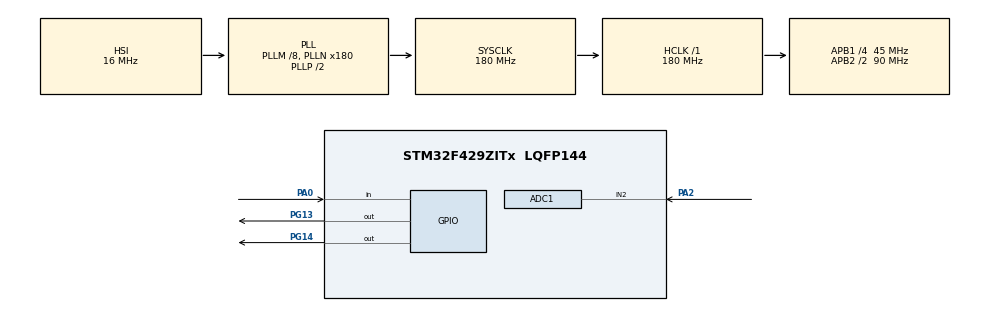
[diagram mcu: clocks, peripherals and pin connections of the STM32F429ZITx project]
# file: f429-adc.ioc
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ADC1.Channel-0\#ChannelRegularConversion=ADC_CHANNEL_2
ADC1.ContinuousConvMode=ENABLE
ADC1.EOCSelection=ADC_EOC_SEQ_CONV
ADC1.NbrOfConversion=1
ADC1.NbrOfConversionFlag=1
ADC1.Rank-0\#ChannelRegularConversion=1
ADC1.Resolution=ADC_RESOLUTION_6B
ADC1.SamplingTime-0\#ChannelRegularConversion=ADC_SAMPLETIME_56CYCLES
ADC1.master=1
Mcu.Family=STM32F4
Mcu.Name=STM32F429ZITx
Mcu.Package=LQFP144
NVIC.PriorityGroup=NVIC_PRIORITYGROUP_4
PA0/WKUP.Signal=GPIO_Input
PA2.Signal=ADCx_IN2
PG13.GPIO_Speed=GPIO_SPEED_FREQ_VERY_HIGH
PG13.Signal=GPIO_Output
PG14.GPIO_Speed=GPIO_SPEED_FREQ_VERY_HIGH
PG14.Signal=GPIO_Output
PH0/OSC_IN.Mode=HSE-External-Oscillator
PH0/OSC_IN.Signal=RCC_OSC_IN
PH1/OSC_OUT.Mode=HSE-External-Oscillator
PH1/OSC_OUT.Signal=RCC_OSC_OUT
ProjectManager.HeapSize=0x200
ProjectManager.StackSize=0x400
ProjectManager.TargetToolchain=MDK-ARM V5.27
RCC.48MHZClocksFreq_Value=90000000
RCC.AHBFreq_Value=180000000
RCC.APB1CLKDivider=RCC_HCLK_DIV4
RCC.APB1Freq_Value=45000000
RCC.APB1TimFreq_Value=90000000
RCC.APB2CLKDivider=RCC_HCLK_DIV2
RCC.APB2Freq_Value=90000000
RCC.APB2TimFreq_Value=180000000
RCC.CortexFreq_Value=180000000
RCC.HCLKFreq_Value=180000000
RCC.HSE_VALUE=8000000
RCC.HSI_VALUE=16000000
RCC.LSE_VALUE=32768
RCC.PLLM=8
RCC.PLLN=180
RCC.SYSCLKFreq_VALUE=180000000
RCC.SYSCLKSource=RCC_SYSCLKSOURCE_PLLCLK
RCC.VCOOutputFreq_Value=360000000
SH.ADCx_IN2.0=ADC1_IN2,IN2
board=custom

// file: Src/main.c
/* USER CODE BEGIN Header */
/**
  ******************************************************************************
  * @file           : main.c
  * @brief          : Main program body
  ******************************************************************************
  * @attention
  *
  * <h2><center>&copy; Copyright (c) 2020 STMicroelectronics.
  * All rights reserved.</center></h2>
  *
  * This software component is licensed by ST under BSD 3-Clause license,
  * the "License"; You may not use this file except in compliance with the
  * License. You may obtain a copy of the License at:
  *                        opensource.org/licenses/BSD-3-Clause
  *
  ******************************************************************************
  */
/* USER CODE END Header */

#include "main.h"

/* USER CODE BEGIN PTD */

int ADC_Value = 0;

/* USER CODE END PTD */

ADC_HandleTypeDef hadc1;

void SystemClock_Config(void);
static void MX_GPIO_Init(void);
static void MX_ADC1_Init(void);

int main(void)
{

  /* MCU Configuration--------------------------------------------------------*/

  /* Reset of all peripherals, Initializes the Flash interface and the Systick. */
  HAL_Init();

  /* Configure the system clock */
  SystemClock_Config();

  /* Initialize all configured peripherals */
  MX_GPIO_Init();
  MX_ADC1_Init();
  /* USER CODE BEGIN 2 */

	HAL_ADC_Start(&hadc1);

	HAL_GPIO_WritePin(GPIOG, GPIO_PIN_14, GPIO_PIN_SET);

  /* USER CODE END 2 */

  /* Infinite loop */
  while (1)
  {

    /* USER CODE BEGIN 3 */

		if(HAL_ADC_PollForConversion(&hadc1, 100) == HAL_OK)
		{

			ADC_Value = HAL_ADC_GetValue(&hadc1);

		}

		if(HAL_GPIO_ReadPin(GPIOA, GPIO_PIN_0))
		{
			while(HAL_GPIO_ReadPin(GPIOA, GPIO_PIN_0));
			HAL_Delay(100);
			HAL_GPIO_TogglePin(GPIOG, GPIO_PIN_13);
			HAL_GPIO_TogglePin(GPIOG, GPIO_PIN_14);

		}

  }
  /* USER CODE END 3 */
}

void SystemClock_Config(void)
{
  RCC_OscInitTypeDef RCC_OscInitStruct = {0};
  RCC_ClkInitTypeDef RCC_ClkInitStruct = {0};

  /** Configure the main internal regulator output voltage
  */
  __HAL_RCC_PWR_CLK_ENABLE();
  __HAL_PWR_VOLTAGESCALING_CONFIG(PWR_REGULATOR_VOLTAGE_SCALE1);
  /** Initializes the CPU, AHB and APB busses clocks
  */
  RCC_OscInitStruct.OscillatorType = RCC_OSCILLATORTYPE_HSI;
  RCC_OscInitStruct.HSIState = RCC_HSI_ON;
  RCC_OscInitStruct.HSICalibrationValue = RCC_HSICALIBRATION_DEFAULT;
  RCC_OscInitStruct.PLL.PLLState = RCC_PLL_ON;
  RCC_OscInitStruct.PLL.PLLSource = RCC_PLLSOURCE_HSI;
  RCC_OscInitStruct.PLL.PLLM = 8;
  RCC_OscInitStruct.PLL.PLLN = 180;
  RCC_OscInitStruct.PLL.PLLP = RCC_PLLP_DIV2;
  RCC_OscInitStruct.PLL.PLLQ = 4;
  if (HAL_RCC_OscConfig(&RCC_OscInitStruct) != HAL_OK)
  {
    Error_Handler();
  }
  /** Activate the Over-Drive mode
  */
  if (HAL_PWREx_EnableOverDrive() != HAL_OK)
  {
    Error_Handler();
  }
  /** Initializes the CPU, AHB and APB busses clocks
  */
  RCC_ClkInitStruct.ClockType = RCC_CLOCKTYPE_HCLK|RCC_CLOCKTYPE_SYSCLK
                              |RCC_CLOCKTYPE_PCLK1|RCC_CLOCKTYPE_PCLK2;
  RCC_ClkInitStruct.SYSCLKSource = RCC_SYSCLKSOURCE_PLLCLK;
  RCC_ClkInitStruct.AHBCLKDivider = RCC_SYSCLK_DIV1;
  RCC_ClkInitStruct.APB1CLKDivider = RCC_HCLK_DIV4;
  RCC_ClkInitStruct.APB2CLKDivider = RCC_HCLK_DIV2;

  if (HAL_RCC_ClockConfig(&RCC_ClkInitStruct, FLASH_LATENCY_5) != HAL_OK)
  {
    Error_Handler();
  }
}

static void MX_ADC1_Init(void)
{

  ADC_ChannelConfTypeDef sConfig = {0};

  /** Configure the global features of the ADC (Clock, Resolution, Data Alignment and number of conversion)
  */
  hadc1.Instance = ADC1;
  hadc1.Init.ClockPrescaler = ADC_CLOCK_SYNC_PCLK_DIV4;
  hadc1.Init.Resolution = ADC_RESOLUTION_8B;
  hadc1.Init.ScanConvMode = DISABLE;
  hadc1.Init.ContinuousConvMode = ENABLE;
  hadc1.Init.DiscontinuousConvMode = DISABLE;
  hadc1.Init.ExternalTrigConvEdge = ADC_EXTERNALTRIGCONVEDGE_NONE;
  hadc1.Init.ExternalTrigConv = ADC_SOFTWARE_START;
  hadc1.Init.DataAlign = ADC_DATAALIGN_RIGHT;
  hadc1.Init.NbrOfConversion = 1;
  hadc1.Init.DMAContinuousRequests = DISABLE;
  hadc1.Init.EOCSelection = ADC_EOC_SEQ_CONV;
  if (HAL_ADC_Init(&hadc1) != HAL_OK)
  {
    Error_Handler();
  }
  /** Configure for the selected ADC regular channel its corresponding rank in the sequencer and its sample time.
  */
  sConfig.Channel = ADC_CHANNEL_2;
  sConfig.Rank = 1;
  sConfig.SamplingTime = ADC_SAMPLETIME_56CYCLES;
  if (HAL_ADC_ConfigChannel(&hadc1, &sConfig) != HAL_OK)
  {
    Error_Handler();
  }

}

static void MX_GPIO_Init(void)
{
  GPIO_InitTypeDef GPIO_InitStruct = {0};

  /* GPIO Ports Clock Enable */
  __HAL_RCC_GPIOH_CLK_ENABLE();
  __HAL_RCC_GPIOA_CLK_ENABLE();
  __HAL_RCC_GPIOG_CLK_ENABLE();

  /*Configure GPIO pin Output Level */
  HAL_GPIO_WritePin(GPIOG, GPIO_PIN_13|GPIO_PIN_14, GPIO_PIN_RESET);

  /*Configure GPIO pin : PA0 */
  GPIO_InitStruct.Pin = GPIO_PIN_0;
  GPIO_InitStruct.Mode = GPIO_MODE_INPUT;
  GPIO_InitStruct.Pull = GPIO_NOPULL;
  HAL_GPIO_Init(GPIOA, &GPIO_InitStruct);

  /*Configure GPIO pins : PG13 PG14 */
  GPIO_InitStruct.Pin = GPIO_PIN_13|GPIO_PIN_14;
  GPIO_InitStruct.Mode = GPIO_MODE_OUTPUT_PP;
  GPIO_InitStruct.Pull = GPIO_NOPULL;
  GPIO_InitStruct.Speed = GPIO_SPEED_FREQ_VERY_HIGH;
  HAL_GPIO_Init(GPIOG, &GPIO_InitStruct);

}

void Error_Handler(void)
{
}

/************************ (C) COPYRIGHT STMicroelectronics *****END OF FILE****/
